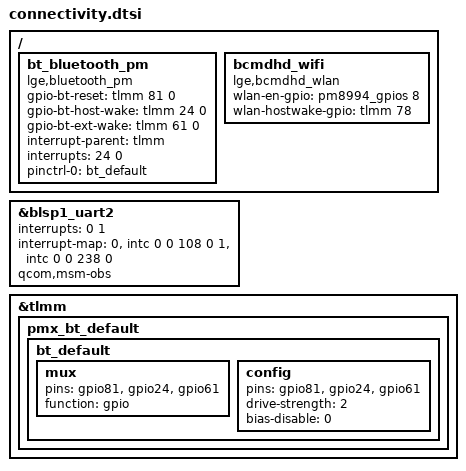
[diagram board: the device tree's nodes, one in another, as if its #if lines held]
/* Copyright (c) 2015, The Linux Foundation. All rights reserved.
 *
 * This program is free software; you can redistribute it and/or modify
 * it under the terms of the GNU General Public License version 2 and
 * only version 2 as published by the Free Software Foundation.
 *
 * This program is distributed in the hope that it will be useful,
 * but WITHOUT ANY WARRANTY; without even the implied warranty of
 * MERCHANTABILITY or FITNESS FOR A PARTICULAR PURPOSE.  See the
 * GNU General Public License for more details.
 */

&blsp1_uart2 {
	interrupt-names = "core_irq", "bam_irq";
	interrupts = <0 1>;
	interrupt-map = <0 &intc 0 0 108 0
			1 &intc 0 0 238 0>;
	/delete-property/ qcom,inject-rx-on-wakeup;
	/delete-property/ qcom,rx-char-to-inject;
	qcom,msm-obs;
};

#ifdef CONFIG_BRCM_V4L2
/ {
	bt_bluetooth_pm {
		compatible = "lge,bluetooth_pm";
		gpio-bt-reset = <&tlmm 81 0>;
		gpio-bt-host-wake = <&tlmm 24 0>;
#ifdef CONFIG_MACH_MSM8996_H1_KDDI_JP
		gpio-bt-ext-wake = <&tlmm 61 0>;
#else
		gpio-bt-ext-wake = <&tlmm 92 0>;
#endif
		interrupt-parent = <&tlmm>;
		interrupts = <24 0>;
		interrupt-names = "host_wake_interrupt";

		pinctrl-names = "bt_default";
		pinctrl-0 = <&bt_default>;
	};
#else
/ {
	bluesleep {
		compatible = "qcom,bluesleep";
		interrupt-parent = <&tlmm>;
		interrupts = <24 0>;
		interrupt-names = "host_wake_int";
		bt_host_wake = <&tlmm 24 0>; /* BT_HOST_WAKE */
#ifdef CONFIG_MACH_MSM8996_H1_KDDI_JP
		bt_ext_wake = <&tlmm 61 0>; /* BT_DEV_WAKE */
#else
		bt_ext_wake = <&tlmm 92 0>; /* BT_DEV_WAKE */
#endif
		pinctrl-names = "default", "sleep";
		pinctrl-0 = <&bt_default>;
		pinctrl-1 = <&bt_sleep>;
	};

	bcm43xx {
		compatible = "bcm,bcm43xx";
		bcm,reg-on-gpio = <&tlmm 81 0>; /* BT_REG_ON */
		pinctrl-names = "default", "sleep";
		pinctrl-0 = <&default_gpio_on>;
		pinctrl-1 = <&sleep_gpio_off>;
	};
#endif

	/* BCMDHD for Wi-Fi */
	bcmdhd_wifi {
		compatible = "lge,bcmdhd_wlan";
		wlan-en-gpio = <&pm8994_gpios 8 0>;
		wlan-hostwake-gpio = <&tlmm 78 0>;
	};
};

&tlmm {
#ifdef CONFIG_BRCM_V4L2
	/* gpio pin mux for bluetooth enable pin */
	pmx_bt_default {
		bt_default: bt_default {
			mux {
#ifdef CONFIG_MACH_MSM8996_H1_KDDI_JP
				pins = "gpio81", "gpio24", "gpio61";
#else
				pins = "gpio81", "gpio24", "gpio92";
#endif
				function = "gpio";
			};

			config {
#ifdef CONFIG_MACH_MSM8996_H1_KDDI_JP
				pins = "gpio81", "gpio24", "gpio61";
#else
				pins = "gpio81", "gpio24", "gpio92";
#endif
				drive-strength = <2>;
				bias-disable = <0>;
			};
		};
	};
#else
	/* gpio enable pin for bluetooth */
	bt_enable_pin {
		default_gpio_on: default_gpio_on {
			mux {
				pins = "gpio81";
				function = "gpio";
			};

			config {
				pins = "gpio81";
				drive-strength = <2>;
				bias-disable;
			};
		};

		sleep_gpio_off: sleep_gpio_off {
			mux {
				pins = "gpio81";
				function = "gpio";
			};

			config {
				pins = "gpio81";
				drive-strength = <2>;
				bias-disable;
			};
		};
	};

	/* gpio pin mux for bluetooth */
	pmx_bt_default {
		bt_default: bt_default {
			mux {
#ifdef CONFIG_MACH_MSM8996_H1_KDDI_JP
				pins = "gpio24", "gpio61";
#else
				pins = "gpio24", "gpio92";
#endif
				function = "gpio";
			};

			config {
#ifdef CONFIG_MACH_MSM8996_H1_KDDI_JP
				pins = "gpio24", "gpio61";
#else
				pins = "gpio24", "gpio92";
#endif
				drive-strength = <2>;
				bias-disable;
			};
		};
	};

	pmx_bt_sleep {
		bt_sleep: bt_sleep {
			mux {
#ifdef CONFIG_MACH_MSM8996_H1_KDDI_JP
				pins = "gpio24", "gpio61";
#else
				pins = "gpio24", "gpio92";
#endif
				function = "gpio";
			};

			config {
#ifdef CONFIG_MACH_MSM8996_H1_KDDI_JP
				pins = "gpio24", "gpio61";
#else
				pins = "gpio24", "gpio92";
#endif
				drive-strength = <2>;
				bias-disable;
			};
		};
	};
#endif
};
